# AU302PDF51 register map
File version: 1.0
Registers are 32-bit, access per field, reset 0x0 unless marked. A register's access mark holds for its fields unless they carry their own. Offsets are from the block's base; [hi:lo] are bit positions.

## UART0 — UART
Base 0x14000000
Same registers: UART1 0x14001000, UART2 0x14002000
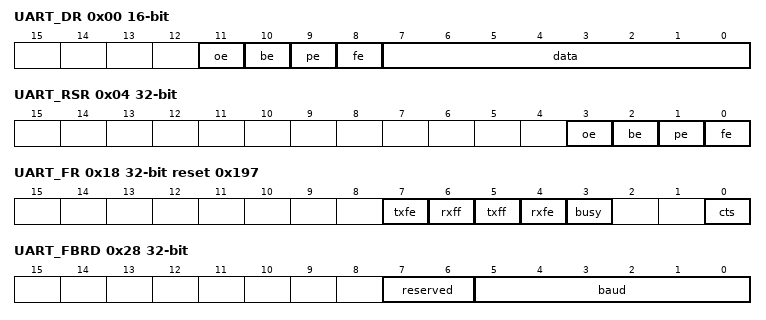
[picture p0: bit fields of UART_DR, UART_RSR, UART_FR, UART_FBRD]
0x00 UART_DR 16-bit — UART_DR 为 UART 数据寄存器，存放接收数据和发送数据，同时可以从该寄存器中 读出接收状态。对于要发送的数据，占据 8bit 寄存器空间；对于接收到的数据，占据12bit 寄存器空间。
  [11] oe ro — 溢出错误。 0：无溢出错误； 1：有溢出错误，即接收 FIFO 满后接收到了数据。
  [10] be ro — break错误。 0：无break错误； 1：有break错误，即接收数据的输入保持低的时间比一个全字传输（包括 start、data、parity、stop bit）还要长。
  [9] pe ro — 校验错误。 0：无校验错误； 1：有校验错误。
  [8] fe ro — 帧错误。 0：无帧错误； 1：有帧错误（错误的停止位）。
  [7:0] data rw — 接收数据和发送数据。
0x04 UART_RSR — 接收状态寄存器/错误清除寄存器。
  [3] oe rw — 溢出错误。 0：无溢出错误； 1：溢出错误。 当 FIFO 满时，FIFO 中的内容保持有效，因为不会有下一个数据写到 FIFO 中，只是移位寄存器会溢出。CPU 必须立刻读数据以腾空 FIFO。
  [2] be rw — Break 错误。 0：无 break 错误； 1：break 错误。 Break 的条件：接收数据的输入保持低的时间比一个全字传输（定义了 start、data、parity、stop bit）还要长。
  [1] pe rw — 校验错误。 0：无校验错误； 1：接收数据的校验错误。 FIFO 模式下，该错误与 FIFO 顶部的数据相关联。
  [0] fe rw — 帧错误。 0：无帧错误； 1：接收到的数据的停止位错误（有效的停 止位为 1）。
0x18 UART_FR reset 0x197 — UART 标志寄存器。
  [7] txfe rw — 该位的含义由 UART_LCR_H[fen]的状态决定。 如果 UART_LCR_H[fen]为 0，则当发送保持寄存器空时该位置 1； 如果 UART_LCR_H[fen]为 1，则当发送 FIFO 为空时该位置 1。
  [6] rxff rw — 该位的含义由 UART_LCR_H[fen]的状态决定。 如果 UART_LCR_H[fen]为 0，则当接收保持寄存器满时该位置 1； 如果 UART_LCR_H[fen]为 1，则当接收 FIFO 为满时该位置 1。
  [5] txff rw — 该位的含义由 UART_LCR_H[fen]的状态决定。 如果 UART_LCR_H[fen]为 0，则当发送保持寄存器满时该位置 1； 如果 UART_LCR_H[fen]为 1，当发送FIFO 为满时该位置 1。
  [4] rxfe rw — 该位的含义由 UART_LCR_H[fen]的状态决定。 如果 UART_LCR_H[fen]为 0，则当接收保持寄存器空时该 bit 置 1； 如果 UART_LCR_H[fen]为 1，则当接收 FIFO 为空时该位就置 1。
  [3] busy rw — UART 忙闲状态位。 0：UART 空闲或者完成发送数据； 1：UART 正忙于发送数据。 该位一旦置位，该状态一直保持到整个字节（包括所有的停止位）完全从移位寄存器中发送出去。 一旦发送 FIFO 非空该位就置位，不管UART 使能与否。
  [0] cts ro — CTS 状态位。只对支持硬件流控的 UART有效，为输入 CTS 管脚的状态取反。
0x24 UART_IBRD rw — 整数波特率寄存器。
  [15:0] baud divint — 整数波特率分频值。复位时全部清 0。
0x28 UART_FBRD — 小数波特率寄存器。
  [7:6] reserved ro — 保留。
  [5:0] baud divfrac rw — 小数波特率分频值。复位时全部清 0。
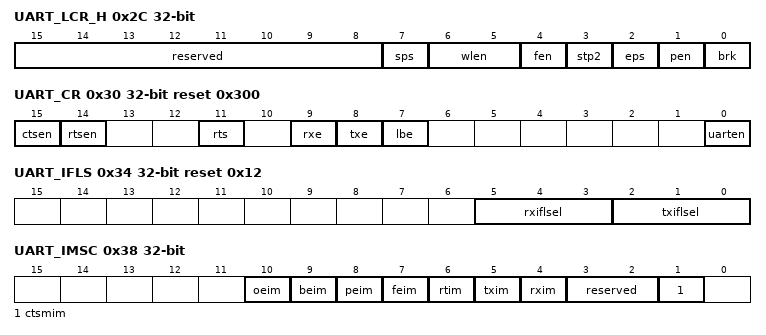
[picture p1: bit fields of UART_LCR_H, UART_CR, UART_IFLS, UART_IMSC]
0x2C UART_LCR_H — 线控寄存器，UART_LCR_H、UART_IBRD和UART_FBRD组成一个30bit宽的寄存器UART_LCR。UART_LCR只有在对UART_LCR_H写入后才会刷新。因此，如果更新UART_IBRD和UART_FBRD的内容，必须同时更新UART_LCR_H。
  [15:8] reserved ro — 保留。
  [7] sps rw — stick parity 选择。 当本寄存器的 bit[1]、 bit[2]、 bit[7]被置位时，校验位就会作为 0 发送和检测； 当本寄存器的 bit[1]、 bit[7]被置位，bit[2]为 0 时，校验位就会作为 1 发送和检测； 当本寄存器的 bit[7]为 0 时， stick parity 禁止。
  [6:5] wlen rw — 指示发送和接收一个帧内数据比特的数目。 00：5bit； 01：6bit； 10：7bit； 11：8bit。
  [4] fen rw — 发送和接收 FIFO 使能控制。 0：不使能发送和接收 FIFO； 1：使能发送和接收 FIFO。
  [3] stp2 rw — 发送帧尾停止位比特选择。 0：发送的帧尾接 1bit 停止位； 1：发送的帧尾接 2bit 停止位。 接收逻辑在接收时不检查 2bit 的停止位。
  [2] eps rw — 发送和接收过程中的奇偶校验选择。 0：在发送和接收过程中生成奇校验或检查奇校验； 1：在发送和接收过程中生成偶校验或检查偶校验。 当 UART_LCR_H[pen]为 0 时，该位不起作用。
  [1] pen rw — 校验选择位。 0：不作校验； 1：发送方向产生校验，接收方向作校验检查。
  [0] brk rw — 发送 break。 0：无效； 1：在完成当前数据的发送后，TXD 连续输出低电平。 注意： 要正确的执行 break 命令，软件将该位置1 的时间必须超过 2 个完整帧；在正常使用中，该位必须清 0。
0x30 UART_CR reset 0x300 — UART 控制寄存器。
  [15] ctsen rw — CTS 硬件流控使能。 0：不使能 CTS 硬件流控； 1：使能 CTS 硬件流控，只有当nUARTCTS 信号有效时才发送数据。
  [14] rtsen rw — RTS 硬件流控使能。 0：不使能 RTS 硬件流控； 1：使能 RTS 硬件流控，只有当接收 FIFO有空间时才请求接收数据。
  [11] rts rw — 请求发送。 该 bit 为 UART modem 状态输出信号nUARTRTS 的取反。 0：输出信号不变； 1：即该 bit 配置为 1，则输出信号为 0。
  [9] rxe rw — UART 接收使能。 0：禁止； 1：使能。 在接收的过程中如果 UART 被禁止，则当前数据的接收就会在正常停止之前结束。
  [8] txe rw — UART 发送使能。 0：禁止； 1：使能。 在发送的过程中如果 UART 被禁止，则当前数据的发送就会在正常停止之前结束。
  [7] lbe rw — 环回使能。 0：禁止； 1：UARTTXD 输出内部环回到UARTRXD。
  [0] uarten rw — UART 使能。 0：禁止； 1：使能。 如果在发送和接收过程中将 UART 禁止，则会在正常停止之前结束当前数据的传送。
0x34 UART_IFLS reset 0x12 — 中断 FIFO 阈值选择寄存器。
  [5:3] rxiflsel rw — 接收中断 FIFO 的阈值选择，接收中断的触发点如下。 000：接收 FIFO≥1/8full； 001：接收 FIFO≥1/4full； 010：接收 FIFO≥1/2full； 011：接收 FIFO≥3/4full； 100：接收 FIFO≥7/8full； 101：接收 FIFO≥1/16full； 110：接收 FIFO≥1/32full； 111：保留。
  [2:0] txiflsel rw — 发送中断 FIFO 的阈值选择，发送中断的触发点如下。 000：发送 FIFO≤1/8full； 001：发送 FIFO≤1/4full； 010：发送 FIFO≤1/2full； 011：发送 FIFO≤3/4full； 100：发送 FIFO≤7/8full； 101：发送 FIFO≤15/16full； 110：发送 FIFO≤31/32full； 111：保留。
0x38 UART_IMSC — 中断屏蔽寄存器。
  [10] oeim rw — 溢出错误中断的屏蔽状态。 0：屏蔽该中断； 1：不屏蔽该中断。
  [9] beim rw — break 错误中断的屏蔽状态。 0：屏蔽该中断； 1：不屏蔽该中断。
  [8] peim rw — 校验中断的屏蔽状态。 0：屏蔽该中断； 1：不屏蔽该中断。
  [7] feim rw — 帧错误中断的屏蔽状态。 0：屏蔽该中断； 1：不屏蔽该中断。
  [6] rtim rw — 接收超时中断的屏蔽状态。 0：屏蔽该中断； 1：不屏蔽该中断。
  [5] txim rw — 发送中断的屏蔽状态。 0：屏蔽该中断； 1：不屏蔽该中断。
  [4] rxim rw — 接收中断的屏蔽状态。 0：屏蔽该中断； 1：不屏蔽该中断。
  [3:2] reserved ro — 保留。
  [1] ctsmim rw — CTS 中断的屏蔽状态。 0：屏蔽该中断； 1：不屏蔽该中断。
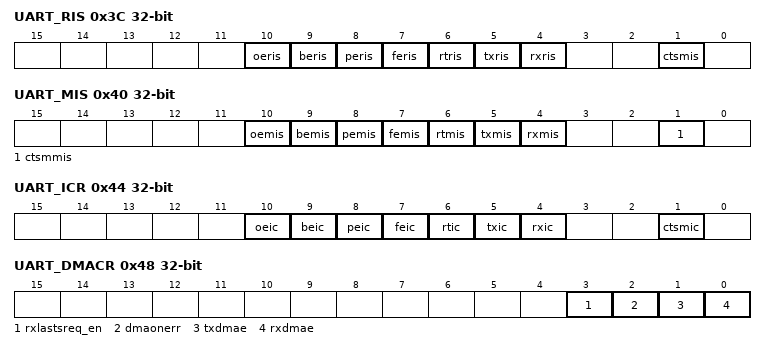
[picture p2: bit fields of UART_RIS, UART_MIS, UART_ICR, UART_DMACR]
0x3C UART_RIS ro — 原始中断状态寄存器，其内容不受中断屏蔽寄存器的影响。
  [10] oeris — 原始的溢出错误中断状态。 0：未产生中断； 1：已产生中断。
  [9] beris — 原始的 break 错误中断状态。 0：未产生中断； 1：已产生中断。
  [8] peris — 原始的校验中断状态。 0：未产生中断； 1：已产生中断。
  [7] feris — 原始的帧错误中断状态。 0：未产生中断； 1：已产生中断。
  [6] rtris — 原始的接收超时中断状态。 0：未产生中断； 1：已产生中断。
  [5] txris — 原始的发送中断状态。 0：未产生中断； 1：已产生中断。
  [4] rxris — 原始的接收中断状态。 0：未产生中断； 1：已产生中断。
  [1] ctsmis — 原始的 CTS 中断状态。 0：未产生中断； 1：已产生中断。
0x40 UART_MIS ro — 屏蔽后中断状态寄存器，其内容为原始中断状态和中断屏蔽进行“与”操作后的结果。
  [10] oemis — 屏蔽后的溢出错误中断状态。 0：未产生中断； 1：已产生中断。
  [9] bemis — 屏蔽后的 break 错误中断状态。 0：未产生中断； 1：已产生中断。
  [8] pemis — 屏蔽后的校验中断状态。 0：未产生中断； 1：已产生中断。
  [7] femis — 屏蔽后的帧错误中断状态。 0：未产生中断； 1：已产生中断。
  [6] rtmis — 屏蔽后的接收超时中断状态。 0：未产生中断； 1：已产生中断。
  [5] txmis — 屏蔽后的发送中断状态。 0：未产生中断； 1：已产生中断。
  [4] rxmis — 屏蔽后的接收中断状态。 0：未产生中断； 1：已产生中断。
  [1] ctsmmis — 屏蔽后的 CTS 中断状态。 0：未产生中断； 1：已产生中断。
0x44 UART_ICR — 中断清除寄存器，写 1 时相应的中断被清除，写 0 则不起作用。对于溢出错误中断，除了对此寄存器 bit[10]写 1 以清除原始溢出错误中断外，还需要写UART_RSR[oe]以清除溢出错误状态。
  [10] oeic wo — 清除溢出错误中断。 0：无效； 1：清除中断。
  [9] beic wo — 清除 break 错误中断。 0：无效； 1：清除中断。
  [8] peic wo — 清除校验中断。 0：无效； 1：清除中断。
  [7] feic wo — 清除帧错误中断。 0：无效； 1：清除中断。
  [6] rtic wo — 清除接收超时中断。 0：无效； 1：清除中断。
  [5] txic wo — 清除发送中断。 0：无效； 1：清除中断。
  [4] rxic wo — 清除接收中断。0：无效；1：清除中断。
  [1] ctsmic ro — 清除 CTS 中断。 0：无效； 1：清除中断。
0x48 UART_DMACR — DMA 控制寄存器，用于配置发送 FIFO 和接收 FIFO 的 DMA 使能。
  [3] rxlastsreq_en rw — UART RX DMA 支持最后一笔数据的 REQ使能。使能打开后，传输最后一笔数据时会发出 LASTREQ 给 DMA 控制器。可以自动对 DMA 进行硬件流控。 0：禁止； 1：使能。
  [2] dmaonerr rw — UART 错误中断出现时的接收通道 DMA 使能控制。 0：当 UART 错误中断有效时，接收通道 DMA 的请求输出有效； 1：当 UART 错误中断有效时，接收通道 DMA 的请求输出无效。
  [1] txdmae rw — 发送 FIFO 的 DMA 使能控制。 0：禁止； 1：使能。
  [0] rxdmae rw — 接收 FIFO 的 DMA 使能控制。 0：禁止； 1：使能。
